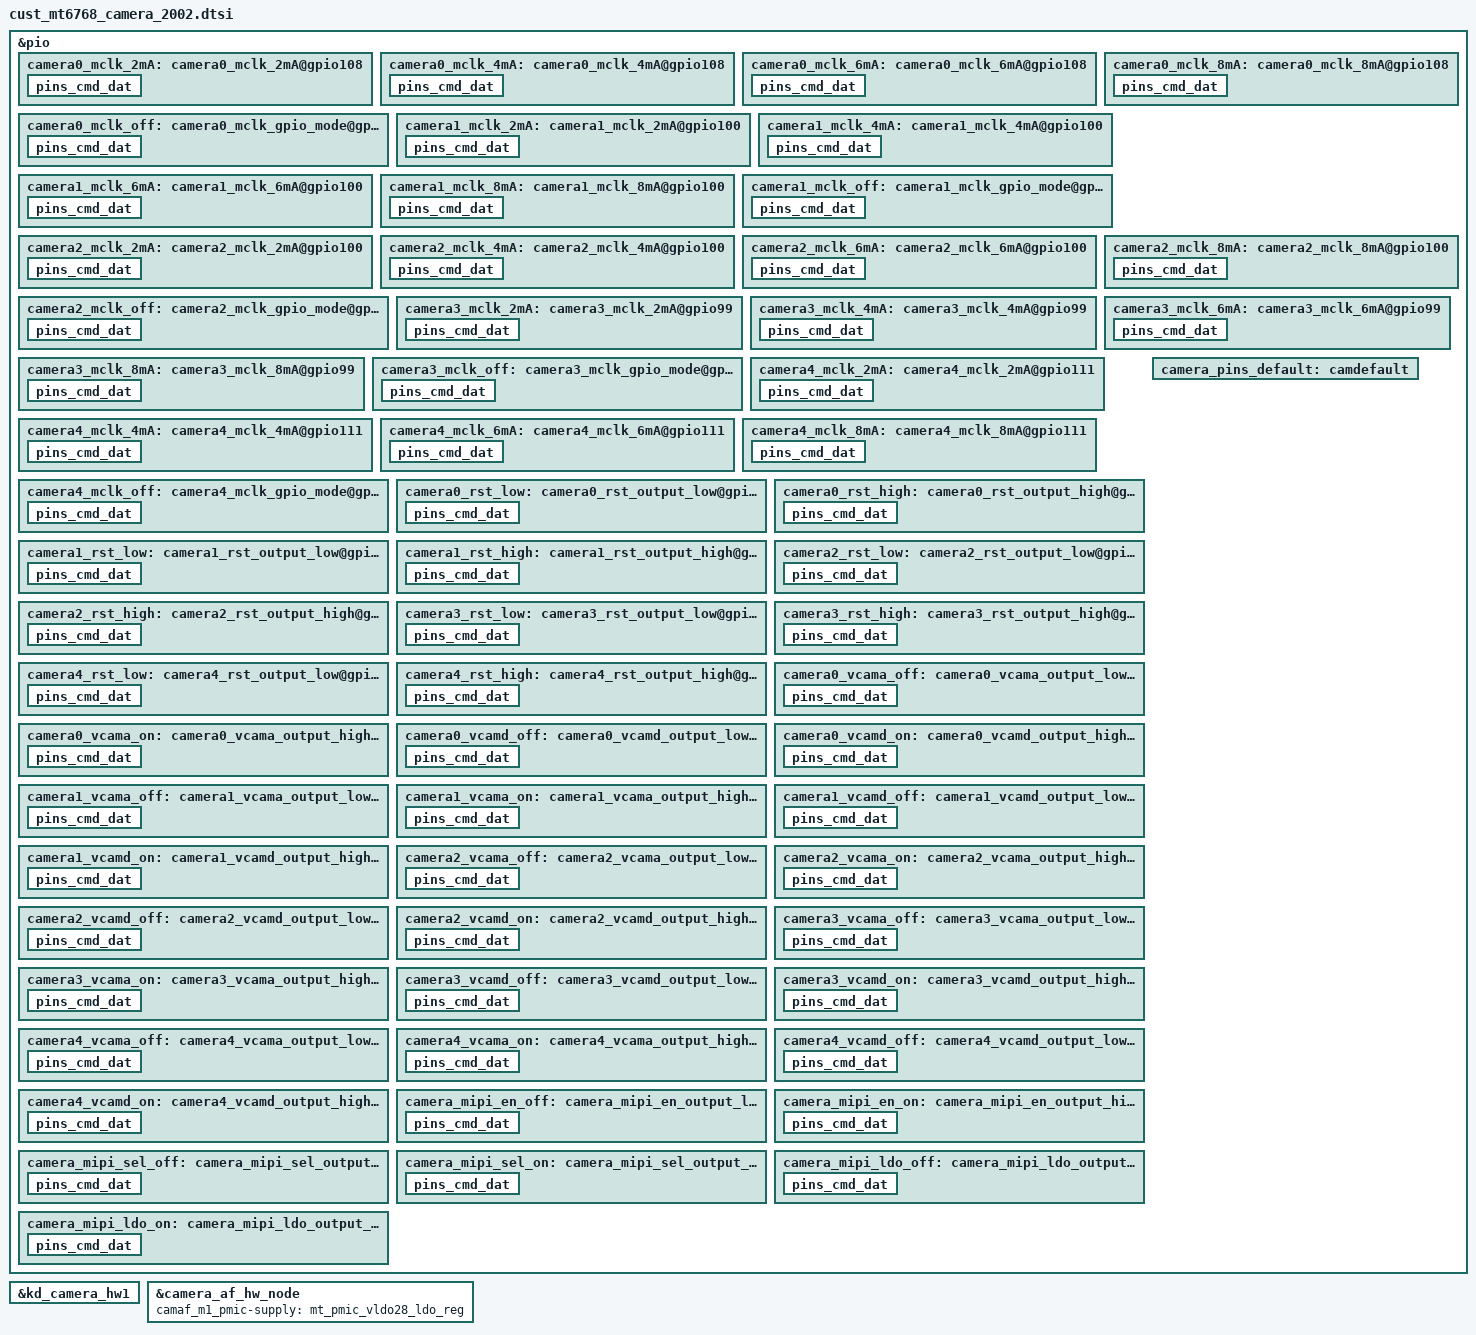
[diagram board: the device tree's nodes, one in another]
/*
 * Copyright (c) 2019 MediaTek Inc.
 *
 * This program is free software; you can redistribute it and/or modify
 * it under the terms of the GNU General Public License version 2 as
 * published by the Free Software Foundation.
 *
 * This program is distributed in the hope that it will be useful,
 * but WITHOUT ANY WARRANTY; without even the implied warranty of
 * MERCHANTABILITY or FITNESS FOR A PARTICULAR PURPOSE.  See the
 * GNU General Public License for more details.
 */
/* CAMERA GPIO standardization */
&pio {
	/* CLK */
	camera0_mclk_2mA: camera0_mclk_2mA@gpio108 {
		pins_cmd_dat {
			pinmux = <PINMUX_GPIO108__FUNC_CMMCLK2>;
			drive-strength = <MTK_DRIVE_2mA>;
		};
	};
	camera0_mclk_4mA: camera0_mclk_4mA@gpio108 {
		pins_cmd_dat {
			pinmux = <PINMUX_GPIO108__FUNC_CMMCLK2>;
			drive-strength = <MTK_DRIVE_4mA>;
		};
	};
	camera0_mclk_6mA: camera0_mclk_6mA@gpio108 {
		pins_cmd_dat {
			pinmux = <PINMUX_GPIO108__FUNC_CMMCLK2>;
			drive-strength = <MTK_DRIVE_6mA>;
		};
	};
	camera0_mclk_8mA: camera0_mclk_8mA@gpio108 {
		pins_cmd_dat {
			pinmux = <PINMUX_GPIO108__FUNC_CMMCLK2>;
			drive-strength = <7>;
		};
	};
	camera0_mclk_off: camera0_mclk_gpio_mode@gpio108 {
		pins_cmd_dat {
			pinmux = <PINMUX_GPIO108__FUNC_GPIO108>;
			drive-strength = <MTK_DRIVE_4mA>;
		};
	};
	camera1_mclk_2mA: camera1_mclk_2mA@gpio100 {
		pins_cmd_dat {
			pinmux = <PINMUX_GPIO100__FUNC_CMMCLK1>;
			drive-strength = <MTK_DRIVE_2mA>;
		};
	};
	camera1_mclk_4mA: camera1_mclk_4mA@gpio100 {
		pins_cmd_dat {
			pinmux = <PINMUX_GPIO100__FUNC_CMMCLK1>;
			drive-strength = <MTK_DRIVE_4mA>;
		};
	};
	camera1_mclk_6mA: camera1_mclk_6mA@gpio100 {
		pins_cmd_dat {
			pinmux = <PINMUX_GPIO100__FUNC_CMMCLK1>;
			drive-strength = <MTK_DRIVE_6mA>;
		};
	};
	camera1_mclk_8mA: camera1_mclk_8mA@gpio100 {
		pins_cmd_dat {
			pinmux = <PINMUX_GPIO100__FUNC_CMMCLK1>;
			drive-strength = <7>;
		};
	};
	camera1_mclk_off: camera1_mclk_gpio_mode@gpio100 {
		pins_cmd_dat {
			pinmux = <PINMUX_GPIO100__FUNC_GPIO100>;
			drive-strength = <MTK_DRIVE_4mA>;
		};
	};
	camera2_mclk_2mA: camera2_mclk_2mA@gpio100 {
		pins_cmd_dat {
			pinmux = <PINMUX_GPIO100__FUNC_CMMCLK1>;
			drive-strength = <MTK_DRIVE_2mA>;
		};
	};
	camera2_mclk_4mA: camera2_mclk_4mA@gpio100 {
		pins_cmd_dat {
			pinmux = <PINMUX_GPIO100__FUNC_CMMCLK1>;
			drive-strength = <MTK_DRIVE_4mA>;
		};
	};
	camera2_mclk_6mA: camera2_mclk_6mA@gpio100 {
		pins_cmd_dat {
			pinmux = <PINMUX_GPIO100__FUNC_CMMCLK1>;
			drive-strength = <MTK_DRIVE_6mA>;
		};
	};
	camera2_mclk_8mA: camera2_mclk_8mA@gpio100 {
		pins_cmd_dat {
			pinmux = <PINMUX_GPIO100__FUNC_CMMCLK1>;
			drive-strength = <7>;
		};
	};
	camera2_mclk_off: camera2_mclk_gpio_mode@gpio100 {
		pins_cmd_dat {
			pinmux = <PINMUX_GPIO100__FUNC_GPIO100>;
			drive-strength = <MTK_DRIVE_4mA>;
		};
	};
	camera3_mclk_2mA: camera3_mclk_2mA@gpio99 {
		pins_cmd_dat {
			pinmux = <PINMUX_GPIO99__FUNC_CMMCLK0>;
			drive-strength = <MTK_DRIVE_2mA>;
		};
	};
	camera3_mclk_4mA: camera3_mclk_4mA@gpio99 {
		pins_cmd_dat {
			pinmux = <PINMUX_GPIO99__FUNC_CMMCLK0>;
			drive-strength = <MTK_DRIVE_4mA>;
		};
	};
	camera3_mclk_6mA: camera3_mclk_6mA@gpio99 {
		pins_cmd_dat {
			pinmux = <PINMUX_GPIO99__FUNC_CMMCLK0>;
			drive-strength = <MTK_DRIVE_6mA>;
		};
	};
	camera3_mclk_8mA: camera3_mclk_8mA@gpio99 {
		pins_cmd_dat {
			pinmux = <PINMUX_GPIO99__FUNC_CMMCLK0>;
			drive-strength = <7>;
		};
	};
	camera3_mclk_off: camera3_mclk_gpio_mode@gpio99 {
		pins_cmd_dat {
			pinmux = <PINMUX_GPIO99__FUNC_GPIO99>;
			drive-strength = <MTK_DRIVE_4mA>;
		};
	};
	camera4_mclk_2mA: camera4_mclk_2mA@gpio111 {
		pins_cmd_dat {
			pinmux = <PINMUX_GPIO111__FUNC_CMMCLK3>;
			drive-strength = <MTK_DRIVE_2mA>;
		};
	};
	camera4_mclk_4mA: camera4_mclk_4mA@gpio111 {
		pins_cmd_dat {
			pinmux = <PINMUX_GPIO111__FUNC_CMMCLK3>;
			drive-strength = <MTK_DRIVE_4mA>;
		};
	};
	camera4_mclk_6mA: camera4_mclk_6mA@gpio111 {
		pins_cmd_dat {
			pinmux = <PINMUX_GPIO111__FUNC_CMMCLK3>;
			drive-strength = <MTK_DRIVE_6mA>;
		};
	};
	camera4_mclk_8mA: camera4_mclk_8mA@gpio111 {
		pins_cmd_dat {
			pinmux = <PINMUX_GPIO111__FUNC_CMMCLK3>;
			drive-strength = <7>;
		};
	};
	camera4_mclk_off: camera4_mclk_gpio_mode@gpio111 {
		pins_cmd_dat {
			pinmux = <PINMUX_GPIO111__FUNC_GPIO111>;
			drive-strength = <MTK_DRIVE_4mA>;
		};
	};
	/* RST & PDN */
	camera0_rst_low: camera0_rst_output_low@gpio109 {
		pins_cmd_dat {
			pinmux = <PINMUX_GPIO109__FUNC_GPIO109>;
			output-low;
		};
	};
	camera0_rst_high: camera0_rst_output_high@gpio109 {
		pins_cmd_dat {
			pinmux = <PINMUX_GPIO109__FUNC_GPIO109>;
			output-high;
		};
	};
	camera1_rst_low: camera1_rst_output_low@gpio102 {
		pins_cmd_dat {
			pinmux = <PINMUX_GPIO102__FUNC_GPIO102>;
			output-low;
		};
	};
	camera1_rst_high: camera1_rst_output_high@gpio102 {
		pins_cmd_dat {
			pinmux = <PINMUX_GPIO102__FUNC_GPIO102>;
			output-high;
		};
	};
	camera2_rst_low: camera2_rst_output_low@gpio107 {
		pins_cmd_dat {
			pinmux = <PINMUX_GPIO107__FUNC_GPIO107>;
			output-low;
		};
	};
	camera2_rst_high: camera2_rst_output_high@gpio107 {
		pins_cmd_dat {
			pinmux = <PINMUX_GPIO107__FUNC_GPIO107>;
			output-high;
		};
	};
	camera3_rst_low: camera3_rst_output_low@gpio101 {
		pins_cmd_dat {
			pinmux = <PINMUX_GPIO101__FUNC_GPIO101>;
			output-low;
		};
	};
	camera3_rst_high: camera3_rst_output_high@gpio101 {
		pins_cmd_dat {
			pinmux = <PINMUX_GPIO101__FUNC_GPIO101>;
			output-high;
		};
	};
	camera4_rst_low: camera4_rst_output_low@gpio112 {
		pins_cmd_dat {
			pinmux = <PINMUX_GPIO112__FUNC_GPIO112>;
			output-low;
		};
	};
	camera4_rst_high: camera4_rst_output_high@gpio112 {
		pins_cmd_dat {
			pinmux = <PINMUX_GPIO112__FUNC_GPIO112>;
			output-high;
		};
	};
	/* VCAMA & VCAMD & VCAMIO */
	camera0_vcama_off: camera0_vcama_output_low@gpio152 {
		pins_cmd_dat {
			pinmux = <PINMUX_GPIO152__FUNC_GPIO152>;
			output-low;
		};
	};
	camera0_vcama_on: camera0_vcama_output_high@gpio152 {
		pins_cmd_dat {
			pinmux = <PINMUX_GPIO152__FUNC_GPIO152>;
			output-high;
		};
	};
	camera0_vcamd_off: camera0_vcamd_output_low@gpio178 {
		pins_cmd_dat {
			pinmux = <PINMUX_GPIO178__FUNC_GPIO178>;
			output-low;
		};
	};
	camera0_vcamd_on: camera0_vcamd_output_high@gpio178 {
		pins_cmd_dat {
			pinmux = <PINMUX_GPIO178__FUNC_GPIO178>;
			output-high;
		};
	};
	camera1_vcama_off: camera1_vcama_output_low@gpio151 {
		pins_cmd_dat {
			pinmux = <PINMUX_GPIO151__FUNC_GPIO151>;
			output-low;
		};
	};
	camera1_vcama_on: camera1_vcama_output_high@gpio151 {
		pins_cmd_dat {
			pinmux = <PINMUX_GPIO151__FUNC_GPIO151>;
			output-high;
		};
	};
	camera1_vcamd_off: camera1_vcamd_output_low@gpio179 {
		pins_cmd_dat {
			pinmux = <PINMUX_GPIO179__FUNC_GPIO179>;
			output-low;
		};
	};
	camera1_vcamd_on: camera1_vcamd_output_high@gpio179 {
		pins_cmd_dat {
			pinmux = <PINMUX_GPIO179__FUNC_GPIO179>;
			output-high;
		};
	};
	camera2_vcama_off: camera2_vcama_output_low@gpio39 {
		pins_cmd_dat {
			pinmux = <PINMUX_GPIO39__FUNC_GPIO39>;
			output-low;
		};
	};
	camera2_vcama_on: camera2_vcama_output_high@gpio39 {
		pins_cmd_dat {
			pinmux = <PINMUX_GPIO39__FUNC_GPIO39>;
			output-high;
		};
	};
	camera2_vcamd_off: camera2_vcamd_output_low@gpio14 {
		pins_cmd_dat {
			pinmux = <PINMUX_GPIO14__FUNC_GPIO14>;
			output-low;
		};
	};
	camera2_vcamd_on: camera2_vcamd_output_high@gpio14 {
		pins_cmd_dat {
			pinmux = <PINMUX_GPIO14__FUNC_GPIO14>;
			output-high;
		};
	};
	camera3_vcama_off: camera3_vcama_output_low@gpio39 {
		pins_cmd_dat {
			pinmux = <PINMUX_GPIO39__FUNC_GPIO39>;
			output-low;
		};
	};
	camera3_vcama_on: camera3_vcama_output_high@gpio39 {
		pins_cmd_dat {
			pinmux = <PINMUX_GPIO39__FUNC_GPIO39>;
			output-high;
		};
	};
	camera3_vcamd_off: camera3_vcamd_output_low@gpio40 {
		pins_cmd_dat {
			pinmux = <PINMUX_GPIO40__FUNC_GPIO40>;
			output-low;
		};
	};
	camera3_vcamd_on: camera3_vcamd_output_high@gpio40 {
		pins_cmd_dat {
			pinmux = <PINMUX_GPIO40__FUNC_GPIO40>;
			output-high;
		};
	};
	camera4_vcama_off: camera4_vcama_output_low@gpio39 {
		pins_cmd_dat {
			pinmux = <PINMUX_GPIO39__FUNC_GPIO39>;
			output-low;
		};
	};
	camera4_vcama_on: camera4_vcama_output_high@gpio39 {
		pins_cmd_dat {
			pinmux = <PINMUX_GPIO39__FUNC_GPIO39>;
			output-high;
		};
	};
	camera4_vcamd_off: camera4_vcamd_output_low@gpio38 {
		pins_cmd_dat {
			pinmux = <PINMUX_GPIO38__FUNC_GPIO38>;
			output-low;
		};
	};
	camera4_vcamd_on: camera4_vcamd_output_high@gpio38 {
		pins_cmd_dat {
			pinmux = <PINMUX_GPIO38__FUNC_GPIO38>;
			output-high;
		};
	};
	camera_mipi_en_off: camera_mipi_en_output_low@gpio36 {
        pins_cmd_dat {
            pinmux = <PINMUX_GPIO36__FUNC_GPIO36>;
            output-low;
        };
    };
    camera_mipi_en_on: camera_mipi_en_output_high@gpio36 {
        pins_cmd_dat {
            pinmux = <PINMUX_GPIO36__FUNC_GPIO36>;
            output-high;
        };
    };
    camera_mipi_sel_off: camera_mipi_sel_output_low@gpio37 {
        pins_cmd_dat {
            pinmux = <PINMUX_GPIO37__FUNC_GPIO37>;
            output-low;
        };
    };
    camera_mipi_sel_on: camera_mipi_sel_output_high@gpio37 {
        pins_cmd_dat {
            pinmux = <PINMUX_GPIO37__FUNC_GPIO37>;
            output-high;
        };
    };
    camera_mipi_ldo_off: camera_mipi_ldo_output_low@gpio150 {
        pins_cmd_dat {
            pinmux = <PINMUX_GPIO150__FUNC_GPIO150>;
            output-low;
        };
    };
    camera_mipi_ldo_on: camera_mipi_ldo_output_high@gpio150 {
        pins_cmd_dat {
            pinmux = <PINMUX_GPIO150__FUNC_GPIO150>;
            output-high;
        };
    };
	camera_pins_default: camdefault {
	};

};

&kd_camera_hw1 {
	pinctrl-names = "default",
			"cam0_mclk_off",
			"cam0_mclk_2mA", "cam0_mclk_4mA",
			"cam0_mclk_6mA", "cam0_mclk_8mA",
			"cam1_mclk_off",
			"cam1_mclk_2mA", "cam1_mclk_4mA",
			"cam1_mclk_6mA", "cam1_mclk_8mA",
			"cam2_mclk_off",
			"cam2_mclk_2mA", "cam2_mclk_4mA",
			"cam2_mclk_6mA", "cam2_mclk_8mA",
			"cam3_mclk_off",
			"cam3_mclk_2mA", "cam3_mclk_4mA",
			"cam3_mclk_6mA", "cam3_mclk_8mA",
			"cam4_mclk_off",
			"cam4_mclk_2mA", "cam4_mclk_4mA",
			"cam4_mclk_6mA", "cam4_mclk_8mA",
			"cam0_rst0", "cam0_rst1",
			"cam1_rst0", "cam1_rst1",
			"cam2_rst0", "cam2_rst1",
			"cam3_rst0", "cam3_rst1",
			"cam4_rst0", "cam4_rst1",
			"cam0_vcama_on", "cam0_vcama_off",
			"cam0_vcamd_on", "cam0_vcamd_off",
			"cam1_vcama_on", "cam1_vcama_off",
			"cam1_vcamd_on", "cam1_vcamd_off",
			"cam2_vcama_on", "cam2_vcama_off",
			"cam2_vcamd_on", "cam2_vcamd_off",
			"cam3_vcama_on", "cam3_vcama_off",
			"cam3_vcamd_on", "cam3_vcamd_off",
			"cam4_vcama_on", "cam4_vcama_off",
			"cam4_vcamd_on", "cam4_vcamd_off",
			"cam_mipi_switch_en_1", "cam_mipi_switch_en_0",
			"cam_mipi_switch_sel_1", "cam_mipi_switch_sel_0",
			"cam_mipi_switch_ldo_1", "cam_mipi_switch_ldo_0";

	pinctrl-0 = <&camera_pins_default>;
	pinctrl-1 = <&camera0_mclk_off>;
	pinctrl-2 = <&camera0_mclk_2mA>;
	pinctrl-3 = <&camera0_mclk_4mA>;
	pinctrl-4 = <&camera0_mclk_6mA>;
	pinctrl-5 = <&camera0_mclk_8mA>;
	pinctrl-6 = <&camera1_mclk_off>;
	pinctrl-7 = <&camera1_mclk_2mA>;
	pinctrl-8 = <&camera1_mclk_4mA>;
	pinctrl-9 = <&camera1_mclk_6mA>;
	pinctrl-10 = <&camera1_mclk_8mA>;
	pinctrl-11 = <&camera2_mclk_off>;
	pinctrl-12 = <&camera2_mclk_2mA>;
	pinctrl-13 = <&camera2_mclk_4mA>;
	pinctrl-14 = <&camera2_mclk_6mA>;
	pinctrl-15 = <&camera2_mclk_8mA>;
	pinctrl-16 = <&camera3_mclk_off>;
	pinctrl-17 = <&camera3_mclk_2mA>;
	pinctrl-18 = <&camera3_mclk_4mA>;
	pinctrl-19 = <&camera3_mclk_6mA>;
	pinctrl-20 = <&camera3_mclk_8mA>;
	pinctrl-21 = <&camera4_mclk_off>;
	pinctrl-22 = <&camera4_mclk_2mA>;
	pinctrl-23 = <&camera4_mclk_4mA>;
	pinctrl-24 = <&camera4_mclk_6mA>;
	pinctrl-25 = <&camera4_mclk_8mA>;
	pinctrl-26 = <&camera0_rst_low>;
	pinctrl-27 = <&camera0_rst_high>;
	pinctrl-28 = <&camera1_rst_low>;
	pinctrl-29 = <&camera1_rst_high>;
	pinctrl-30 = <&camera2_rst_low>;
	pinctrl-31 = <&camera2_rst_high>;
	pinctrl-32 = <&camera3_rst_low>;
	pinctrl-33 = <&camera3_rst_high>;
	pinctrl-34 = <&camera4_rst_low>;
	pinctrl-35 = <&camera4_rst_high>;
	pinctrl-36 = <&camera0_vcama_on>;
	pinctrl-37 = <&camera0_vcama_off>;
	pinctrl-38 = <&camera0_vcamd_on>;
	pinctrl-39 = <&camera0_vcamd_off>;
	pinctrl-40 = <&camera1_vcama_on>;
	pinctrl-41 = <&camera1_vcama_off>;
	pinctrl-42 = <&camera1_vcamd_on>;
	pinctrl-43 = <&camera1_vcamd_off>;
	pinctrl-44 = <&camera2_vcama_on>;
	pinctrl-45 = <&camera2_vcama_off>;
	pinctrl-46 = <&camera2_vcamd_on>;
	pinctrl-47 = <&camera2_vcamd_off>;
	pinctrl-48 = <&camera3_vcama_on>;
	pinctrl-49 = <&camera3_vcama_off>;
	pinctrl-50 = <&camera3_vcamd_on>;
	pinctrl-51 = <&camera3_vcamd_off>;
	pinctrl-52 = <&camera4_vcama_on>;
	pinctrl-53 = <&camera4_vcama_off>;
	pinctrl-54 = <&camera4_vcamd_on>;
	pinctrl-55 = <&camera4_vcamd_off>;
	pinctrl-56 = <&camera_mipi_en_on>;
	pinctrl-57 = <&camera_mipi_en_off>;
	pinctrl-58 = <&camera_mipi_sel_on>;
	pinctrl-59 = <&camera_mipi_sel_off>;
	pinctrl-60 = <&camera_mipi_ldo_on>;
	pinctrl-61 = <&camera_mipi_ldo_off>;

	cam0_vcamio-supply = <&mt_pmic_vcamio_ldo_reg>;
	cam1_vcamio-supply = <&mt_pmic_vcamio_ldo_reg>;
	cam2_vcamio-supply = <&mt_pmic_vcamio_ldo_reg>;
	cam3_vcamio-supply = <&mt_pmic_vcamio_ldo_reg>;
	cam4_vcamio-supply = <&mt_pmic_vcamio_ldo_reg>;

	// Antaiui <AI_BSP_CAM> <xieht> <2021-03-02> enable list begin
	cam0_enable_sensor = "s5kjn1sq03_mipi_raw s5kgm1st_mipi_raw";
	cam1_enable_sensor = "gc8034_mipi_raw s5k4h8_mipi_raw";
	cam2_enable_sensor = "gc02m1b_mipi_raw gc02m2_mipi_raw";
	cam3_enable_sensor = "gc02m1micro_mipi_raw ov2680_mipi_raw";
	cam4_enable_sensor = "gc5035_mipi_raw s5k5e8yx_mipi_raw";
	// Antaiui <AI_BSP_CAM> <xieht> <2021-03-02> enable list end

	status = "okay";

};

// Antaiui <AI_BSP_CAM> <xieht> <2022-04-09> 2002 lens porting begin
&camera_af_hw_node {
    camaf_m1_pmic-supply = <&mt_pmic_vldo28_ldo_reg>;
    status = "okay";
};
// Antaiui <AI_BSP_CAM> <xieht> <2022-04-09> 2002 lens porting end

/* CAMERA GPIO end */
